# STM32F102xx register map
File version: 1.1
Registers are 32-bit, read-write, reset 0x0 unless marked. A register's access mark holds for its fields unless they carry their own. Offsets are from the block's base; lines under a group give offsets from that group; [hi:lo] are bit positions; {n}, {i} and the like mark numbered series; 'fields as' and 'values as' point back to an identical list; <NAME> marks a mode.

## Memory map
0x40000000 TIM2 size 0x400 — General purpose timer
0x40000400 TIM3 size 0x400
0x40002800 RTC size 0x400 — Real time clock
0x40002C00 WWDG size 0x400 — Window watchdog
0x40003000 IWDG size 0x400 — Independent watchdog
0x40004400 USART2 size 0x400
0x40005400 I2C1 size 0x400 — Inter integrated circuit
0x40006C04 BKP size 0x400 — Backup registers
0x40007000 PWR size 0x400 — Power control
0x40010000 AFIO size 0x400 — Alternate function I/O
0x40010400 EXTI size 0x400
0x40010800 GPIOA size 0x400 — General purpose I/O
0x40010C00 GPIOB size 0x400
0x40011000 GPIOC size 0x400
0x40011400 GPIOD size 0x400
0x40012400 ADC1 size 0x400 — Analog to digital converter
0x40013000 SPI1 size 0x400 — Serial peripheral interface
0x40013800 USART1 size 0x400 — Universal synchronous asynchronous receiver transmitter
0x40020000 DMA1 size 0x400 — DMA controller
0x40020400 DMA2 size 0x400
0x40021000 RCC size 0x400 — Reset and clock control
0x40022000 FLASH size 0x400
0x40023000 CRC size 0x400 — CRC calculation unit
0xE000E000 NVIC size 0x1001 — Nested Vectored Interrupt Controller
0xE0042000 DBG size 0x400 — Debug support

## Interrupts
0 WWDG_IRQ (WWDG) — Window Watchdog interrupt
1 PVD_IRQ (PWR) — PVD through EXTI line detection interrupt
2 TAMPER_IRQ (EXTI) — Tamper interrupt
3 RTC_IRQ (RTC) — RTC global interrupt
4 FLASH_IRQ (FLASH) — Flash global interrupt
5 RCC_IRQ (RCC) — RCC global interrupt
6 EXTI0_IRQ (EXTI) — EXTI Line0 interrupt
7 EXTI1_IRQ (EXTI) — EXTI Line1 interrupt
8 EXTI2_IRQ (EXTI) — EXTI Line2 interrupt
9 EXTI3_IRQ (EXTI) — EXTI Line3 interrupt
10 EXTI4_IRQ (EXTI) — EXTI Line4 interrupt
11 DMA1_Channel1_IRQ (DMA1) — DMA1 Channel1 global interrupt
12 DMA1_Channel2_IRQ (DMA1) — DMA1 Channel2 global interrupt
13 DMA1_Channel3_IRQ (DMA1) — DMA1 Channel3 global interrupt
14 DMA1_Channel4_IRQ (DMA1) — DMA1 Channel4 global interrupt
15 DMA1_Channel5_IRQ (DMA1) — DMA1 Channel5 global interrupt
16 DMA1_Channel6_IRQ (DMA1) — DMA1 Channel6 global interrupt
17 DMA1_Channel7_IRQ (DMA1) — DMA1 Channel7 global interrupt
18 ADC_IRQ (ADC1) — ADC1 global interrupt
23 EXTI9_5_IRQ (EXTI) — EXTI Line[9:5] interrupts
28 TIM2_IRQ (TIM2) — TIM2 global interrupt
29 TIM3_IRQ (TIM3) — TIM3 global interrupt
31 I2C_EV_IRQ (I2C1) — I2C event interrupt
32 I2C_ER_IRQ (I2C1) — I2C errot interrupt
35 SPI_IRQ (SPI1) — SPI global interrupt
37 USART1_IRQ (USART1) — USART1 global interrupt
38 USART2_IRQ (USART2) — USART2 global interrupt
40 EXTI15_10_IRQ (EXTI) — EXTI Line[15:10] interrupts
41 RTCAlarm_IRQ (RTC) — RTC Alarms through EXTI line interrupt
56 DMA2_Channel1_IRQ (DMA2) — DMA2 Channel1 global interrupt
57 DMA2_Channel2_IRQ (DMA2) — DMA2 Channel2 global interrupt
58 DMA2_Channel3_IRQ (DMA2) — DMA2 Channel3 global interrupt
59 DMA2_Channel4_5_IRQ (DMA2) — DMA2 Channel4 and DMA2 Channel5 global interrupt

## PWR — Power control
Base 0x40007000
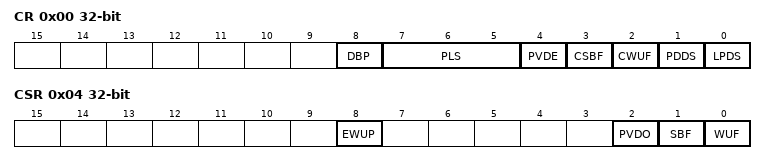
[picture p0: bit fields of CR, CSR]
0x00 CR — Power control register (PWR_CR)
  [8] DBP — Disable Backup Domain write protection
  [7:5] PLS — PVD Level Selection
  [4] PVDE — Power Voltage Detector Enable
  [3] CSBF — Clear STANDBY Flag
  [2] CWUF — Clear Wake-up Flag
  [1] PDDS — Power Down Deep Sleep
  [0] LPDS — Low Power Deep Sleep
0x04 CSR access per field — Power control register (PWR_CR)
  [8] EWUP rw — Enable WKUP pin
  [2] PVDO ro — PVD Output
  [1] SBF ro — STANDBY Flag
  [0] WUF ro — Wake-Up Flag

## GPIOA — General purpose I/O
Base 0x40010800
Same registers: GPIOB 0x40010C00, GPIOC 0x40011000, GPIOD 0x40011400
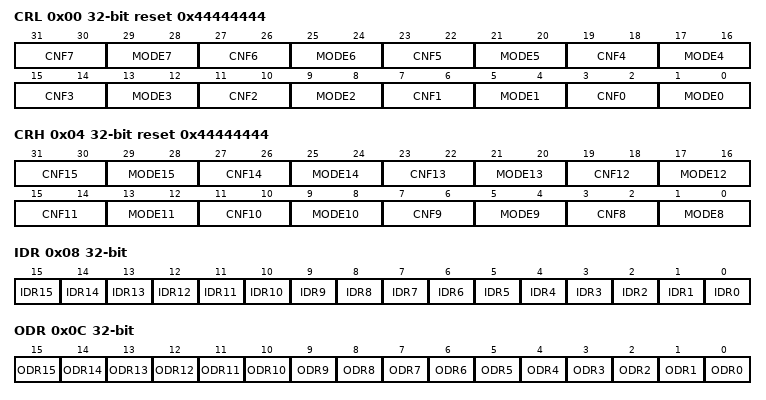
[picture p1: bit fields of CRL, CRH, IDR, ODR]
0x00 CRL reset 0x44444444 — Port configuration register low (GPIOn_CRL)
  [31:30] CNF7 — Port n.7 configuration bits
  [29:28] MODE7 — Port n.7 mode bits
  [27:26] CNF6 — Port n.6 configuration bits
  [25:24] MODE6 — Port n.6 mode bits
  [23:22] CNF5 — Port n.5 configuration bits
  [21:20] MODE5 — Port n.5 mode bits
  [19:18] CNF4 — Port n.4 configuration bits
  [17:16] MODE4 — Port n.4 mode bits
  [15:14] CNF3 — Port n.3 configuration bits
  [13:12] MODE3 — Port n.3 mode bits
  [11:10] CNF2 — Port n.2 configuration bits
  [9:8] MODE2 — Port n.2 mode bits
  [7:6] CNF1 — Port n.1 configuration bits
  [5:4] MODE1 — Port n.1 mode bits
  [3:2] CNF0 — Port n.0 configuration bits
  [1:0] MODE0 — Port n.0 mode bits
0x04 CRH reset 0x44444444 — Port configuration register high (GPIOn_CRL)
  [31:30] CNF15 — Port n.15 configuration bits
  [29:28] MODE15 — Port n.15 mode bits
  [27:26] CNF14 — Port n.14 configuration bits
  [25:24] MODE14 — Port n.14 mode bits
  [23:22] CNF13 — Port n.13 configuration bits
  [21:20] MODE13 — Port n.13 mode bits
  [19:18] CNF12 — Port n.12 configuration bits
  [17:16] MODE12 — Port n.12 mode bits
  [15:14] CNF11 — Port n.11 configuration bits
  [13:12] MODE11 — Port n.11 mode bits
  [11:10] CNF10 — Port n.10 configuration bits
  [9:8] MODE10 — Port n.10 mode bits
  [7:6] CNF9 — Port n.9 configuration bits
  [5:4] MODE9 — Port n.9 mode bits
  [3:2] CNF8 — Port n.8 configuration bits
  [1:0] MODE8 — Port n.8 mode bits
0x08 IDR ro — Port input data register (GPIOn_IDR)
  [n] IDR{n} (n=0..15) — Port input data
0x0C ODR — Port output data register (GPIOn_ODR)
  [n] ODR{n} (n=0..15) — Port output data
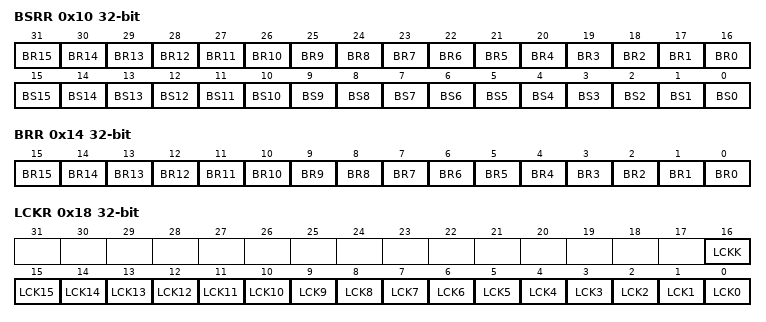
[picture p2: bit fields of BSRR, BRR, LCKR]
0x10 BSRR wo — Port bit set/reset register (GPIOn_BSRR)
  [n+16] BR{n} (n=0..15) — Reset bit {n}
  [n] BS{n} (n=3..15) — Set bit {n}
  [2] BS2 — Set bit 1
  [1] BS1 — Set bit 1
  [0] BS0 — Set bit 0
0x14 BRR wo — Port bit reset register (GPIOn_BRR)
  [n] BR{n} (n=3..15) — Reset bit {n}
  [2] BR2 — Reset bit 1
  [1] BR1 — Reset bit 1
  [0] BR0 — Reset bit 0
0x18 LCKR — Port configuration lock register
  [16] LCKK — Lock key
  [n] LCK{n} (n=0..15) — Port A Lock bit {n}
